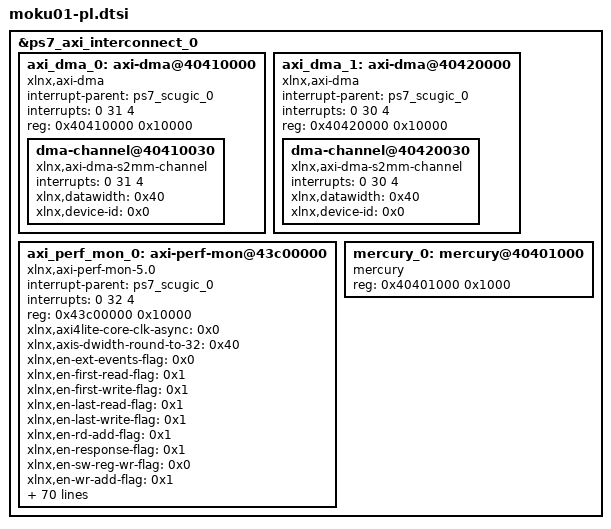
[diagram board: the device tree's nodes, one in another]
/*
 * CAUTION: This file is automatically generated by Xilinx.
 * Version:  
 * Today is: Wed Dec  3 15:57:26 2014
*/

	&ps7_axi_interconnect_0 {
		ranges;
		axi_dma_0: axi-dma@40410000 {
			compatible = "xlnx,axi-dma";
			interrupt-parent = <&ps7_scugic_0>;
			interrupts = <0 31 4>;
			reg = <0x40410000 0x10000>;
			dma-channel@40410030 {
				compatible = "xlnx,axi-dma-s2mm-channel";
				interrupts = <0 31 4>;
				xlnx,datawidth = <0x40>;
				xlnx,device-id = <0x0>;
			} ;
		} ;
		axi_dma_1: axi-dma@40420000 {
			compatible = "xlnx,axi-dma";
			interrupt-parent = <&ps7_scugic_0>;
			interrupts = <0 30 4>;
			reg = <0x40420000 0x10000>;
			dma-channel@40420030 {
				compatible = "xlnx,axi-dma-s2mm-channel";
				interrupts = <0 30 4>;
				xlnx,datawidth = <0x40>;
				xlnx,device-id = <0x0>;
			} ;
		} ;

		axi_perf_mon_0: axi-perf-mon@43c00000 {
			compatible = "xlnx,axi-perf-mon-5.0";
			interrupt-parent = <&ps7_scugic_0>;
			interrupts = <0 32 4>;
			reg = <0x43c00000 0x10000>;
			xlnx,axi4lite-core-clk-async = <0x0>;
			xlnx,axis-dwidth-round-to-32 = <0x40>;
			xlnx,en-ext-events-flag = <0x0>;
			xlnx,en-first-read-flag = <0x1>;
			xlnx,en-first-write-flag = <0x1>;
			xlnx,en-last-read-flag = <0x1>;
			xlnx,en-last-write-flag = <0x1>;
			xlnx,en-rd-add-flag = <0x1>;
			xlnx,en-response-flag = <0x1>;
			xlnx,en-sw-reg-wr-flag = <0x0>;
			xlnx,en-wr-add-flag = <0x1>;
			xlnx,enable-advanced = <0x1>;
			xlnx,enable-event-count = <0x1>;
			xlnx,enable-event-log = <0x0>;
			xlnx,enable-profile = <0x0>;
			xlnx,enable-trace = <0x0>;
			xlnx,ext-event0-fifo-enable = <0x1>;
			xlnx,ext-event1-fifo-enable = <0x1>;
			xlnx,ext-event2-fifo-enable = <0x1>;
			xlnx,ext-event3-fifo-enable = <0x1>;
			xlnx,ext-event4-fifo-enable = <0x1>;
			xlnx,ext-event5-fifo-enable = <0x1>;
			xlnx,ext-event6-fifo-enable = <0x1>;
			xlnx,ext-event7-fifo-enable = <0x1>;
			xlnx,fifo-axis-depth = <0x20>;
			xlnx,fifo-axis-sync = <0x0>;
			xlnx,fifo-axis-tdata-width = <0x38>;
			xlnx,fifo-axis-tid-width = <0x1>;
			xlnx,global-count-width = <0x20>;
			xlnx,have-sampled-metric-cnt = <0x1>;
			xlnx,log-data-offld = <0x0>;
			xlnx,metric-count-scale = <0x1>;
			xlnx,metric-count-width = <0x20>;
			xlnx,metrics-sample-count-width = <0x20>;
			xlnx,num-monitor-slots = <0x2>;
			xlnx,num-of-counters = <0x1>;
			xlnx,reg-all-monitor-signals = <0x0>;
			xlnx,s-axi-id-width = <0x1>;
			xlnx,show-axi-ids = <0x0>;
			xlnx,show-axi-len = <0x0>;
			xlnx,slot-0-axi-addr-width = <0xa>;
			xlnx,slot-0-axi-data-width = <0x20>;
			xlnx,slot-0-axi-id-width = <0x1>;
			xlnx,slot-0-axi-protocol = "AXI4LITE";
			xlnx,slot-0-fifo-enable = <0x0>;
			xlnx,slot-1-axi-addr-width = <0xa>;
			xlnx,slot-1-axi-data-width = <0x20>;
			xlnx,slot-1-axi-id-width = <0x1>;
			xlnx,slot-1-axi-protocol = "AXI4LITE";
			xlnx,slot-1-fifo-enable = <0x0>;
			xlnx,slot-2-axi-addr-width = <0x20>;
			xlnx,slot-2-axi-data-width = <0x20>;
			xlnx,slot-2-axi-id-width = <0x1>;
			xlnx,slot-2-axi-protocol = "AXI4";
			xlnx,slot-2-fifo-enable = <0x1>;
			xlnx,slot-3-axi-addr-width = <0x20>;
			xlnx,slot-3-axi-data-width = <0x20>;
			xlnx,slot-3-axi-id-width = <0x1>;
			xlnx,slot-3-axi-protocol = "AXI4";
			xlnx,slot-3-fifo-enable = <0x1>;
			xlnx,slot-4-axi-addr-width = <0x20>;
			xlnx,slot-4-axi-data-width = <0x20>;
			xlnx,slot-4-axi-id-width = <0x1>;
			xlnx,slot-4-axi-protocol = "AXI4";
			xlnx,slot-4-fifo-enable = <0x1>;
			xlnx,slot-5-axi-addr-width = <0x20>;
			xlnx,slot-5-axi-data-width = <0x20>;
			xlnx,slot-5-axi-id-width = <0x1>;
			xlnx,slot-5-axi-protocol = "AXI4";
			xlnx,slot-5-fifo-enable = <0x1>;
			xlnx,slot-6-axi-addr-width = <0x20>;
			xlnx,slot-6-axi-data-width = <0x20>;
			xlnx,slot-6-axi-id-width = <0x1>;
			xlnx,slot-6-axi-protocol = "AXI4";
			xlnx,slot-6-fifo-enable = <0x1>;
			xlnx,slot-7-axi-addr-width = <0x20>;
			xlnx,slot-7-axi-data-width = <0x20>;
			xlnx,slot-7-axi-id-width = <0x1>;
			xlnx,slot-7-axi-protocol = "AXI4";
			xlnx,slot-7-fifo-enable = <0x1>;
			xlnx,support-id-reflection = <0x0>;
		} ;

		mercury_0: mercury@40401000 {
			compatible = "mercury";
			reg = <0x40401000 0x1000>;
		} ;
	} ;
